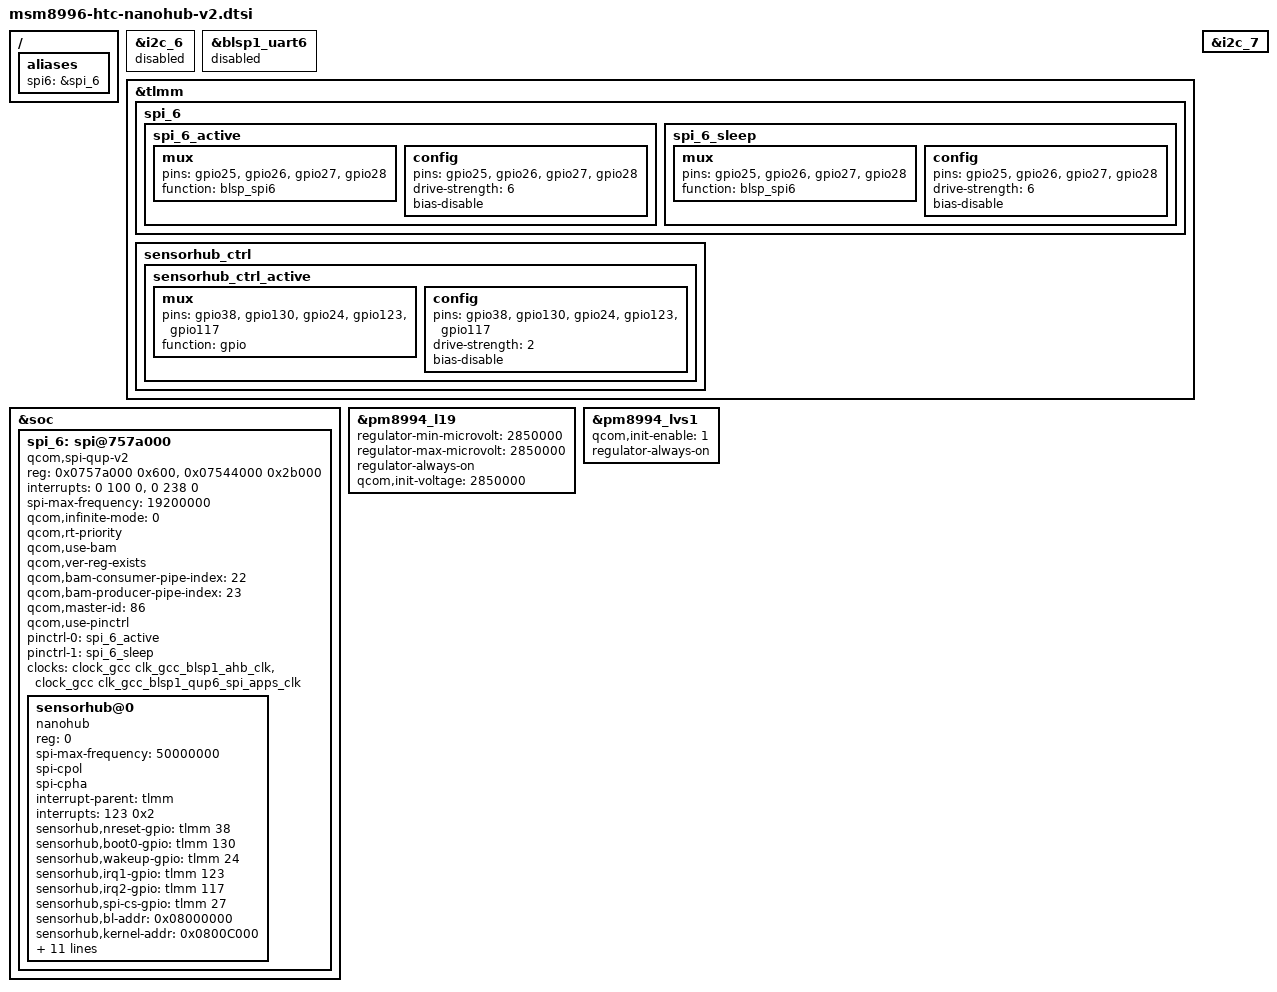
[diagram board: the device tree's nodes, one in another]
/* Copyright (c) 2016, The Linux Foundation. All rights reserved.
 *
 * This program is free software; you can redistribute it and/or modify
 * it under the terms of the GNU General Public License version 2 and
 * only version 2 as published by the Free Software Foundation.
 *
 * This program is distributed in the hope that it will be useful,
 * but WITHOUT ANY WARRANTY; without even the implied warranty of
 * MERCHANTABILITY or FITNESS FOR A PARTICULAR PURPOSE.  See the
 * GNU General Public License for more details.
 */

/*
 * msm8996-htc-nanohub-v2: nanohub config
 */

&i2c_6 {
	status = "disabled";
};

&blsp1_uart6 {
	status = "disabled";
};

/ {
	aliases {
		spi6 = &spi_6;
	};
};

&tlmm {
	spi_6 {
		spi_6_active: spi_6_active {
			mux {
				pins = "gpio25", "gpio26", "gpio27", "gpio28";
				function = "blsp_spi6";
			};

			config {
				pins = "gpio25", "gpio26", "gpio27", "gpio28";
				drive-strength = <6>;
				bias-disable;
			};
		};

		spi_6_sleep: spi_6_sleep {
			mux {
				pins = "gpio25", "gpio26", "gpio27", "gpio28";
				function = "blsp_spi6";
			};

			config {
				pins = "gpio25", "gpio26", "gpio27", "gpio28";
				drive-strength = <6>;
				bias-disable;
			};
		};
	};

	sensorhub_ctrl {
	/* NRST, BOOT0, AP2SH, SH2AP, SH2APNW */
		sensorhub_ctrl_active: sensorhub_ctrl_active {
			mux {
				pins = "gpio38", "gpio130", "gpio24", "gpio123", "gpio117";
				function = "gpio";
			};

			config {
				pins = "gpio38", "gpio130", "gpio24", "gpio123", "gpio117";
				drive-strength = <2>;
				bias-disable;
			};
		};
	};
};

&soc {
	spi_6: spi@757a000 { /* BLSP1 QUP6 */
		compatible = "qcom,spi-qup-v2";
		#address-cells = <1>;
		#size-cells = <0>;
		reg-names = "spi_physical", "spi_bam_physical";
		reg = <0x0757a000 0x600>,
		      <0x07544000 0x2b000>;
		interrupt-names = "spi_irq", "spi_bam_irq";
		interrupts = <0 100 0>, <0 238 0>;
		spi-max-frequency = <19200000>;

		qcom,infinite-mode = <0>;
		qcom,rt-priority;
		qcom,use-bam;
		qcom,ver-reg-exists;
		qcom,bam-consumer-pipe-index = <22>;
		qcom,bam-producer-pipe-index = <23>;
		qcom,master-id = <86>;
		qcom,use-pinctrl;
		pinctrl-names = "spi_default", "spi_sleep";
		pinctrl-0 = <&spi_6_active>;
		pinctrl-1 = <&spi_6_sleep>;

		clock-names = "iface_clk", "core_clk";

		clocks = <&clock_gcc clk_gcc_blsp1_ahb_clk>,
		         <&clock_gcc clk_gcc_blsp1_qup6_spi_apps_clk>;
	};
};

&spi_6 {
	sensorhub@0 {
		compatible = "nanohub";
		reg = <0>;
		spi-max-frequency = <50000000>;
		spi-cpol;
		spi-cpha;

		interrupt-parent = <&tlmm>;
		interrupts = <123 0x2>;
		sensorhub,nreset-gpio = <&tlmm 38 0x00>;
		sensorhub,boot0-gpio = <&tlmm 130 0x00>;
		sensorhub,wakeup-gpio = <&tlmm 24 0x00>;
		sensorhub,irq1-gpio = <&tlmm 123 0x00>;
		sensorhub,irq2-gpio = <&tlmm 117 0x00>;
		sensorhub,spi-cs-gpio = <&tlmm 27 0x00>;
		sensorhub,bl-addr = <0x08000000>;
		sensorhub,kernel-addr = <0x0800C000>;
		sensorhub,shared-addr = <0x08040000>;
		sensorhub,flash-banks = <0 0x08000000 0x04000>,
			<3 0x0800C000 0x04000>,
			<4 0x08010000 0x10000>,
			<5 0x08020000 0x20000>;
		sensorhub,num-flash-banks = <4>;
		sensorhub,shared-flash-banks = <6 0x08040000 0x20000>,
			<7 0x08060000 0x20000>,
			<8 0x08080000 0x20000>,
			<9 0x080A0000 0x20000>,
			<10 0x080C0000 0x20000>,
			<11 0x080E0000 0x20000>;
		sensorhub,num-shared-flash-banks = <6>;

		pinctrl-names = "default";
		pinctrl-0 = <&sensorhub_ctrl_active>;
	};
};

&pm8994_l19 {
	regulator-min-microvolt = <2850000>;
	regulator-max-microvolt = <2850000>;
	regulator-always-on;
	qcom,init-voltage = <2850000>;
	status = "okay";
};

&pm8994_lvs1 {
	qcom,init-enable = <1>;
	regulator-always-on;
	status = "okay";
};

&i2c_7 {
	/delete-node/ silabs4705@11;
};
